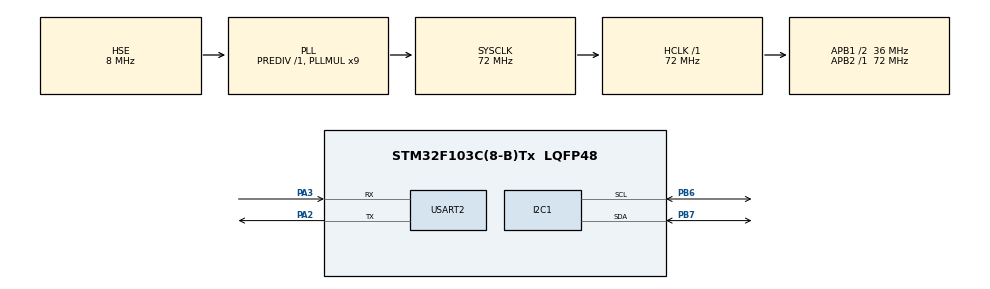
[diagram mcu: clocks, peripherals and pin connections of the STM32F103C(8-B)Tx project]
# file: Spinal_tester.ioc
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Dma.Request0=USART2_TX
Dma.Request1=USART2_RX
Dma.USART2_RX.1.Direction=DMA_PERIPH_TO_MEMORY
Dma.USART2_RX.1.Instance=DMA1_Channel6
Dma.USART2_RX.1.MemDataAlignment=DMA_MDATAALIGN_BYTE
Dma.USART2_RX.1.MemInc=DMA_MINC_ENABLE
Dma.USART2_RX.1.Mode=DMA_CIRCULAR
Dma.USART2_RX.1.PeriphDataAlignment=DMA_PDATAALIGN_BYTE
Dma.USART2_RX.1.PeriphInc=DMA_PINC_DISABLE
Dma.USART2_RX.1.Priority=DMA_PRIORITY_MEDIUM
Dma.USART2_TX.0.Direction=DMA_MEMORY_TO_PERIPH
Dma.USART2_TX.0.Instance=DMA1_Channel7
Dma.USART2_TX.0.MemDataAlignment=DMA_MDATAALIGN_BYTE
Dma.USART2_TX.0.MemInc=DMA_MINC_ENABLE
Dma.USART2_TX.0.Mode=DMA_NORMAL
Dma.USART2_TX.0.PeriphDataAlignment=DMA_PDATAALIGN_BYTE
Dma.USART2_TX.0.PeriphInc=DMA_PINC_DISABLE
Dma.USART2_TX.0.Priority=DMA_PRIORITY_MEDIUM
FREERTOS.Tasks01=defaultTask,0,128,StartDefaultTask,Default,NULL,Dynamic,NULL,NULL
Mcu.Family=STM32F1
Mcu.Name=STM32F103C(8-B)Tx
Mcu.Package=LQFP48
NVIC.DMA1_Channel6_IRQn=true\:6\:0\:true\:false\:true\:true\:false\:true\:true
NVIC.DMA1_Channel7_IRQn=true\:6\:0\:true\:false\:true\:true\:false\:true\:true
NVIC.PriorityGroup=NVIC_PRIORITYGROUP_4
NVIC.TIM2_IRQn=true\:5\:0\:true\:false\:true\:true\:true\:true\:true
NVIC.TIM3_IRQn=true\:6\:0\:true\:false\:true\:true\:true\:true\:true
NVIC.TIM4_IRQn=true\:15\:0\:false\:false\:true\:false\:false\:true\:true
NVIC.TimeBase=TIM4_IRQn
NVIC.TimeBaseIP=TIM4
NVIC.USART2_IRQn=true\:6\:0\:true\:false\:true\:true\:false\:true\:true
PA13.Mode=Serial_Wire
PA13.Signal=SYS_JTMS-SWDIO
PA14.Mode=Serial_Wire
PA14.Signal=SYS_JTCK-SWCLK
PA2.Mode=Asynchronous
PA2.Signal=USART2_TX
PA3.Mode=Asynchronous
PA3.Signal=USART2_RX
PB6.Mode=I2C
PB6.Signal=I2C1_SCL
PB7.Mode=I2C
PB7.Signal=I2C1_SDA
PD0-OSC_IN.Mode=HSE-External-Oscillator
PD0-OSC_IN.Signal=RCC_OSC_IN
PD1-OSC_OUT.Mode=HSE-External-Oscillator
PD1-OSC_OUT.Signal=RCC_OSC_OUT
ProjectManager.HeapSize=0x200
ProjectManager.StackSize=0x400
ProjectManager.TargetToolchain=CMake
RCC.AHBFreq_Value=72000000
RCC.APB1CLKDivider=RCC_HCLK_DIV2
RCC.APB1Freq_Value=36000000
RCC.APB1TimFreq_Value=72000000
RCC.APB2Freq_Value=72000000
RCC.APB2TimFreq_Value=72000000
RCC.HCLKFreq_Value=72000000
RCC.PLLMUL=RCC_PLL_MUL9
RCC.PLLSourceVirtual=RCC_PLLSOURCE_HSE
RCC.SYSCLKFreq_VALUE=72000000
RCC.SYSCLKSource=RCC_SYSCLKSOURCE_PLLCLK
RCC.USBFreq_Value=72000000
TIM3.Prescaler=7199
USART2.VirtualMode=VM_ASYNC
VP_FREERTOS_VS_CMSIS_V1.Mode=CMSIS_V1
VP_SYS_VS_tim4.Mode=TIM4
VP_TIM2_VS_ClockSourceINT.Mode=Internal
VP_TIM3_VS_ClockSourceINT.Mode=Internal
board=custom

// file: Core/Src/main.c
/* USER CODE BEGIN Header */
/**
  ******************************************************************************
  * @file           : main.c
  * @brief          : Main program body
  ******************************************************************************
  * @attention
  *
  * Copyright (c) 2026 STMicroelectronics.
  * All rights reserved.
  *
  * This software is licensed under terms that can be found in the LICENSE file
  * in the root directory of this software component.
  * If no LICENSE file comes with this software, it is provided AS-IS.
  *
  ******************************************************************************
  */
/* USER CODE END Header */
#include "main.h"
#include "cmsis_os.h"

/* USER CODE BEGIN Includes */
#include "app_bootstrap.h"

/* USER CODE END Includes */

I2C_HandleTypeDef hi2c1;

TIM_HandleTypeDef htim2;
TIM_HandleTypeDef htim3;

UART_HandleTypeDef huart2;
DMA_HandleTypeDef hdma_usart2_tx;
DMA_HandleTypeDef hdma_usart2_rx;

osThreadId defaultTaskHandle;

void SystemClock_Config(void);
static void MX_GPIO_Init(void);
static void MX_DMA_Init(void);
static void MX_I2C1_Init(void);
static void MX_USART2_UART_Init(void);
static void MX_TIM2_Init(void);
static void MX_TIM3_Init(void);
void StartDefaultTask(void const * argument);

int main(void)
{

  /* MCU Configuration--------------------------------------------------------*/

  /* Reset of all peripherals, Initializes the Flash interface and the Systick. */
  HAL_Init();

  /* Configure the system clock */
  SystemClock_Config();

  /* Initialize all configured peripherals */
  MX_GPIO_Init();
  MX_DMA_Init();
  MX_I2C1_Init();
  MX_USART2_UART_Init();
  MX_TIM2_Init();
  MX_TIM3_Init();

  /* Create the thread(s) */
  /* definition and creation of defaultTask */
  osThreadDef(defaultTask, StartDefaultTask, osPriorityNormal, 0, 128);
  defaultTaskHandle = osThreadCreate(osThread(defaultTask), NULL);

  /* Start scheduler */
  osKernelStart();

  /* We should never get here as control is now taken by the scheduler */

  /* Infinite loop */
  while (1)
  {

  }
}

void SystemClock_Config(void)
{
  RCC_OscInitTypeDef RCC_OscInitStruct = {0};
  RCC_ClkInitTypeDef RCC_ClkInitStruct = {0};

  /** Initializes the RCC Oscillators according to the specified parameters
  * in the RCC_OscInitTypeDef structure.
  */
  RCC_OscInitStruct.OscillatorType = RCC_OSCILLATORTYPE_HSE;
  RCC_OscInitStruct.HSEState = RCC_HSE_ON;
  RCC_OscInitStruct.HSEPredivValue = RCC_HSE_PREDIV_DIV1;
  RCC_OscInitStruct.HSIState = RCC_HSI_ON;
  RCC_OscInitStruct.PLL.PLLState = RCC_PLL_ON;
  RCC_OscInitStruct.PLL.PLLSource = RCC_PLLSOURCE_HSE;
  RCC_OscInitStruct.PLL.PLLMUL = RCC_PLL_MUL9;
  if (HAL_RCC_OscConfig(&RCC_OscInitStruct) != HAL_OK)
  {
    Error_Handler();
  }

  /** Initializes the CPU, AHB and APB buses clocks
  */
  RCC_ClkInitStruct.ClockType = RCC_CLOCKTYPE_HCLK|RCC_CLOCKTYPE_SYSCLK
                              |RCC_CLOCKTYPE_PCLK1|RCC_CLOCKTYPE_PCLK2;
  RCC_ClkInitStruct.SYSCLKSource = RCC_SYSCLKSOURCE_PLLCLK;
  RCC_ClkInitStruct.AHBCLKDivider = RCC_SYSCLK_DIV1;
  RCC_ClkInitStruct.APB1CLKDivider = RCC_HCLK_DIV2;
  RCC_ClkInitStruct.APB2CLKDivider = RCC_HCLK_DIV1;

  if (HAL_RCC_ClockConfig(&RCC_ClkInitStruct, FLASH_LATENCY_2) != HAL_OK)
  {
    Error_Handler();
  }
}

static void MX_I2C1_Init(void)
{

  hi2c1.Instance = I2C1;
  hi2c1.Init.ClockSpeed = 100000;
  hi2c1.Init.DutyCycle = I2C_DUTYCYCLE_2;
  hi2c1.Init.OwnAddress1 = 0;
  hi2c1.Init.AddressingMode = I2C_ADDRESSINGMODE_7BIT;
  hi2c1.Init.DualAddressMode = I2C_DUALADDRESS_DISABLE;
  hi2c1.Init.OwnAddress2 = 0;
  hi2c1.Init.GeneralCallMode = I2C_GENERALCALL_DISABLE;
  hi2c1.Init.NoStretchMode = I2C_NOSTRETCH_DISABLE;
  if (HAL_I2C_Init(&hi2c1) != HAL_OK)
  {
    Error_Handler();
  }

}

static void MX_TIM2_Init(void)
{

  TIM_ClockConfigTypeDef sClockSourceConfig = {0};
  TIM_MasterConfigTypeDef sMasterConfig = {0};

  htim2.Instance = TIM2;
  htim2.Init.Prescaler = 0;
  htim2.Init.CounterMode = TIM_COUNTERMODE_UP;
  htim2.Init.Period = 65535;
  htim2.Init.ClockDivision = TIM_CLOCKDIVISION_DIV1;
  htim2.Init.AutoReloadPreload = TIM_AUTORELOAD_PRELOAD_DISABLE;
  if (HAL_TIM_Base_Init(&htim2) != HAL_OK)
  {
    Error_Handler();
  }
  sClockSourceConfig.ClockSource = TIM_CLOCKSOURCE_INTERNAL;
  if (HAL_TIM_ConfigClockSource(&htim2, &sClockSourceConfig) != HAL_OK)
  {
    Error_Handler();
  }
  sMasterConfig.MasterOutputTrigger = TIM_TRGO_RESET;
  sMasterConfig.MasterSlaveMode = TIM_MASTERSLAVEMODE_DISABLE;
  if (HAL_TIMEx_MasterConfigSynchronization(&htim2, &sMasterConfig) != HAL_OK)
  {
    Error_Handler();
  }

}

static void MX_TIM3_Init(void)
{

  TIM_ClockConfigTypeDef sClockSourceConfig = {0};
  TIM_MasterConfigTypeDef sMasterConfig = {0};

  htim3.Instance = TIM3;
  htim3.Init.Prescaler = 7199;
  htim3.Init.CounterMode = TIM_COUNTERMODE_UP;
  htim3.Init.Period = 65535;
  htim3.Init.ClockDivision = TIM_CLOCKDIVISION_DIV1;
  htim3.Init.AutoReloadPreload = TIM_AUTORELOAD_PRELOAD_DISABLE;
  if (HAL_TIM_Base_Init(&htim3) != HAL_OK)
  {
    Error_Handler();
  }
  sClockSourceConfig.ClockSource = TIM_CLOCKSOURCE_INTERNAL;
  if (HAL_TIM_ConfigClockSource(&htim3, &sClockSourceConfig) != HAL_OK)
  {
    Error_Handler();
  }
  sMasterConfig.MasterOutputTrigger = TIM_TRGO_RESET;
  sMasterConfig.MasterSlaveMode = TIM_MASTERSLAVEMODE_DISABLE;
  if (HAL_TIMEx_MasterConfigSynchronization(&htim3, &sMasterConfig) != HAL_OK)
  {
    Error_Handler();
  }

}

static void MX_USART2_UART_Init(void)
{

  huart2.Instance = USART2;
  huart2.Init.BaudRate = 115200;
  huart2.Init.WordLength = UART_WORDLENGTH_8B;
  huart2.Init.StopBits = UART_STOPBITS_1;
  huart2.Init.Parity = UART_PARITY_NONE;
  huart2.Init.Mode = UART_MODE_TX_RX;
  huart2.Init.HwFlowCtl = UART_HWCONTROL_NONE;
  huart2.Init.OverSampling = UART_OVERSAMPLING_16;
  if (HAL_UART_Init(&huart2) != HAL_OK)
  {
    Error_Handler();
  }

}

static void MX_DMA_Init(void)
{

  /* DMA controller clock enable */
  __HAL_RCC_DMA1_CLK_ENABLE();

  /* DMA interrupt init */
  /* DMA1_Channel6_IRQn interrupt configuration */
  HAL_NVIC_SetPriority(DMA1_Channel6_IRQn, 6, 0);
  HAL_NVIC_EnableIRQ(DMA1_Channel6_IRQn);
  /* DMA1_Channel7_IRQn interrupt configuration */
  HAL_NVIC_SetPriority(DMA1_Channel7_IRQn, 6, 0);
  HAL_NVIC_EnableIRQ(DMA1_Channel7_IRQn);

}

static void MX_GPIO_Init(void)
{

  /* GPIO Ports Clock Enable */
  __HAL_RCC_GPIOD_CLK_ENABLE();
  __HAL_RCC_GPIOA_CLK_ENABLE();
  __HAL_RCC_GPIOB_CLK_ENABLE();

}

void StartDefaultTask(void const * argument)
{
  /* USER CODE BEGIN 5 */
  AppBootstrapConfig app_config =
  {
    .i2c = &hi2c1,
    .uart = &huart2,
    .timestamp_timer = &htim2
  };

  (void)argument;

  if (AppBootstrap_Start(&app_config) != APP_STATUS_OK)
  {
    /* A bootstrap failure is fatal because application task ownership is undefined. */
    Error_Handler();
  }

  /* CubeMX owns this bootstrap task; application tasks are statically allocated. */
  vTaskDelete(NULL);
  /* USER CODE END 5 */
}

void HAL_TIM_PeriodElapsedCallback(TIM_HandleTypeDef *htim)
{
  if (htim->Instance == TIM4)
  {
    HAL_IncTick();
  }
}

void Error_Handler(void)
{
  __disable_irq();
  while (1)
  {
  }
}
